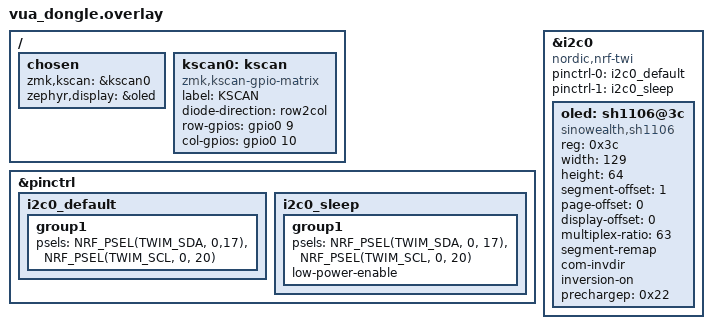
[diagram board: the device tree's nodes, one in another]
/*
*
* Copyright (c) 2021 Darryl deHaan
* SPDX-License-Identifier: MIT
*
*/

#include "vua.dtsi"

/{
    chosen {
        zmk,kscan = &kscan0;
        zephyr,display = &oled;
    };
    kscan0: kscan {
        compatible = "zmk,kscan-gpio-matrix";
        label = "KSCAN";
        diode-direction = "row2col";

        /* one row on P0.09, pulled-down */
        row-gpios = <&gpio0 9 GPIO_ACTIVE_HIGH>;

        /* one column on P0.10, pulled-down */
        col-gpios = <&gpio0 10 (GPIO_ACTIVE_HIGH | GPIO_PULL_DOWN)>;
    };
};

&pinctrl {
    i2c0_default: i2c0_default {
        group1 {
            psels = <NRF_PSEL(TWIM_SDA, 0,17)>,
                <NRF_PSEL(TWIM_SCL, 0, 20)>;
        };
    };

    i2c0_sleep: i2c0_sleep {
        group1 {
            psels = <NRF_PSEL(TWIM_SDA, 0, 17)>,
                <NRF_PSEL(TWIM_SCL, 0, 20)>;
            low-power-enable;
        };
    };	
}; 

&i2c0 {
	status = "okay";
	compatible = "nordic,nrf-twi";
    pinctrl-0 = <&i2c0_default>;
    pinctrl-1 = <&i2c0_sleep>;
	oled: sh1106@3c {
        compatible = "sinowealth,sh1106";
        reg = <0x3c>;
        width = <129>;
        height = <64>;
        segment-offset = <1>;
        page-offset = <0>;
        display-offset = <0>;
        multiplex-ratio = <63>;
        segment-remap;
        com-invdir;
        inversion-on;
        prechargep = <0x22>;
	};
};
